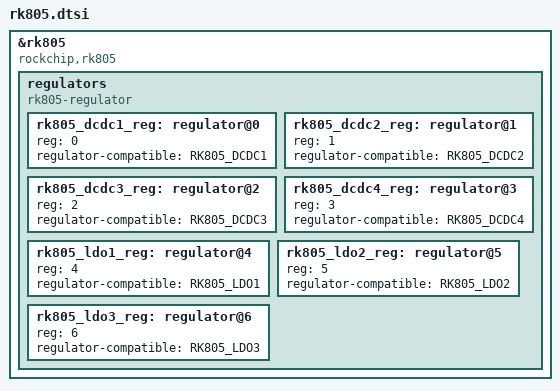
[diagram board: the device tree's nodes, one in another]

&rk805 {
	compatible = "rockchip,rk805";

	regulators {
		#address-cells = <1>;
		#size-cells = <0>;

		compatible = "rk805-regulator";
		rk805_dcdc1_reg: regulator@0 {
			reg = <0>;
			regulator-compatible = "RK805_DCDC1";
		};

		rk805_dcdc2_reg: regulator@1 {
			reg = <1>;
			regulator-compatible = "RK805_DCDC2";
		};

		rk805_dcdc3_reg: regulator@2 {
			reg = <2>;
			regulator-compatible = "RK805_DCDC3";
		};

		rk805_dcdc4_reg: regulator@3 {
			reg = <3>;
			regulator-compatible = "RK805_DCDC4";
		};

		rk805_ldo1_reg: regulator@4 {
			reg = <4>;
			regulator-compatible = "RK805_LDO1";
		};

		rk805_ldo2_reg: regulator@5 {
			reg = <5>;
			regulator-compatible = "RK805_LDO2";
		};

		rk805_ldo3_reg: regulator@6 {
			reg = <6>;
			regulator-compatible = "RK805_LDO3";
		};
	};
};
